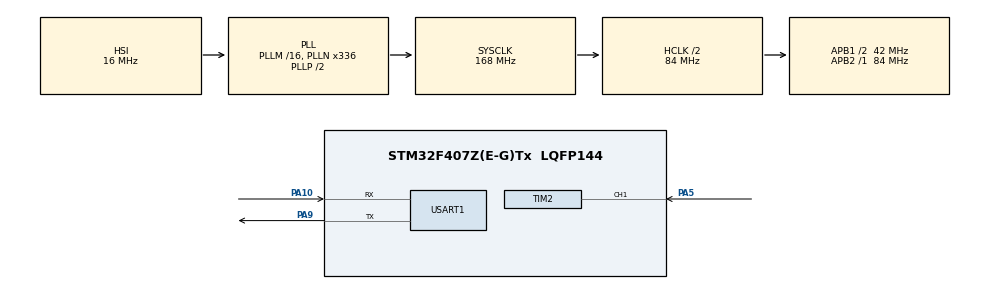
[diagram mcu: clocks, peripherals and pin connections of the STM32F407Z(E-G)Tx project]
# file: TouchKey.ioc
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Mcu.Family=STM32F4
Mcu.Name=STM32F407Z(E-G)Tx
Mcu.Package=LQFP144
NVIC.PriorityGroup=NVIC_PRIORITYGROUP_4
NVIC.TIM2_IRQn=true\:0\:0\:false\:false\:true\:true\:true
PA10.Mode=Asynchronous
PA10.Signal=USART1_RX
PA5.GPIO_Speed=GPIO_SPEED_FREQ_HIGH
PA5.Signal=S_TIM2_CH1_ETR
PA9.Mode=Asynchronous
PA9.Signal=USART1_TX
PC14-OSC32_IN.Mode=LSE-External-Oscillator
PC14-OSC32_IN.Signal=RCC_OSC32_IN
PC15-OSC32_OUT.Mode=LSE-External-Oscillator
PC15-OSC32_OUT.Signal=RCC_OSC32_OUT
PH0-OSC_IN.Mode=HSE-External-Oscillator
PH0-OSC_IN.Signal=RCC_OSC_IN
PH1-OSC_OUT.Mode=HSE-External-Oscillator
PH1-OSC_OUT.Signal=RCC_OSC_OUT
ProjectManager.HeapSize=0x200
ProjectManager.StackSize=0x400
ProjectManager.TargetToolchain=MDK-ARM V5
RCC.48MHZClocksFreq_Value=84000000
RCC.AHBCLKDivider=RCC_SYSCLK_DIV2
RCC.AHBFreq_Value=84000000
RCC.APB1CLKDivider=RCC_HCLK_DIV2
RCC.APB1Freq_Value=42000000
RCC.APB1TimFreq_Value=84000000
RCC.APB2Freq_Value=84000000
RCC.APB2TimFreq_Value=84000000
RCC.CortexFreq_Value=84000000
RCC.HCLKFreq_Value=84000000
RCC.HSE_VALUE=25000000
RCC.HSI_VALUE=16000000
RCC.PLLN=336
RCC.SYSCLKFreq_VALUE=168000000
RCC.SYSCLKSource=RCC_SYSCLKSOURCE_PLLCLK
RCC.VCOOutputFreq_Value=336000000
SH.S_TIM2_CH1_ETR.0=TIM2_CH1,Input_Capture1_from_TI1
TIM2.AutoReloadPreload=TIM_AUTORELOAD_PRELOAD_ENABLE
TIM2.Channel-Input_Capture1_from_TI1=TIM_CHANNEL_1
TIM2.ICFilter_CH1=2
TIM2.Period=1000000000
TIM2.Prescaler=8
USART1.VirtualMode=VM_ASYNC
VP_TIM2_VS_ClockSourceINT.Mode=Internal
board=custom

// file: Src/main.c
/* USER CODE BEGIN Header */
/**
  ******************************************************************************
  * @file           : main.c
  * @brief          : Main program body
  ******************************************************************************
  * @attention
  *
  * <h2><center>&copy; Copyright (c) 2019 STMicroelectronics.
  * All rights reserved.</center></h2>
  *
  * This software component is licensed by ST under BSD 3-Clause license,
  * the "License"; You may not use this file except in compliance with the
  * License. You may obtain a copy of the License at:
  *                        opensource.org/licenses/BSD-3-Clause
  *
  ******************************************************************************
  */
/* USER CODE END Header */

#include "main.h"

/* USER CODE BEGIN Includes */
#include <stdio.h>
#include "TPAD.h"
/* USER CODE END Includes */

/* USER CODE BEGIN PD */
#define TIMEOUT_MAX		1000000000
/* USER CODE END PD */

TIM_HandleTypeDef htim2;

UART_HandleTypeDef huart1;

void SystemClock_Config(void);
static void MX_GPIO_Init(void);
static void MX_TIM2_Init(void);
static void MX_USART1_UART_Init(void);

int main(void)
{
  /* USER CODE BEGIN 1 */
	uint32_t tmp;
  /* USER CODE END 1 */

  /* MCU Configuration--------------------------------------------------------*/

  /* Reset of all peripherals, Initializes the Flash interface and the Systick. */
  HAL_Init();

  /* Configure the system clock */
  SystemClock_Config();

  /* Initialize all configured peripherals */
  MX_GPIO_Init();
  MX_TIM2_Init();
  MX_USART1_UART_Init();
  /* USER CODE BEGIN 2 */
	HAL_TIM_IC_Start_IT(&htim2, TIM_CHANNEL_1);

  /* USER CODE END 2 */

  /* Infinite loop */
  /* USER CODE BEGIN WHILE */
  while (1)
  {

		if(TouchKeyScan(1))
		{
			printf("按下\r\n");
			HAL_Delay(10);
		}
    /* USER CODE END WHILE */

  }
}

void SystemClock_Config(void)
{
  RCC_OscInitTypeDef RCC_OscInitStruct = {0};
  RCC_ClkInitTypeDef RCC_ClkInitStruct = {0};

  /** Configure the main internal regulator output voltage
  */
  __HAL_RCC_PWR_CLK_ENABLE();
  __HAL_PWR_VOLTAGESCALING_CONFIG(PWR_REGULATOR_VOLTAGE_SCALE1);
  /** Initializes the CPU, AHB and APB busses clocks
  */
  RCC_OscInitStruct.OscillatorType = RCC_OSCILLATORTYPE_HSI;
  RCC_OscInitStruct.HSIState = RCC_HSI_ON;
  RCC_OscInitStruct.HSICalibrationValue = RCC_HSICALIBRATION_DEFAULT;
  RCC_OscInitStruct.PLL.PLLState = RCC_PLL_ON;
  RCC_OscInitStruct.PLL.PLLSource = RCC_PLLSOURCE_HSI;
  RCC_OscInitStruct.PLL.PLLM = 16;
  RCC_OscInitStruct.PLL.PLLN = 336;
  RCC_OscInitStruct.PLL.PLLP = RCC_PLLP_DIV2;
  RCC_OscInitStruct.PLL.PLLQ = 4;
  if (HAL_RCC_OscConfig(&RCC_OscInitStruct) != HAL_OK)
  {
    Error_Handler();
  }
  /** Initializes the CPU, AHB and APB busses clocks
  */
  RCC_ClkInitStruct.ClockType = RCC_CLOCKTYPE_HCLK|RCC_CLOCKTYPE_SYSCLK
                              |RCC_CLOCKTYPE_PCLK1|RCC_CLOCKTYPE_PCLK2;
  RCC_ClkInitStruct.SYSCLKSource = RCC_SYSCLKSOURCE_PLLCLK;
  RCC_ClkInitStruct.AHBCLKDivider = RCC_SYSCLK_DIV2;
  RCC_ClkInitStruct.APB1CLKDivider = RCC_HCLK_DIV2;
  RCC_ClkInitStruct.APB2CLKDivider = RCC_HCLK_DIV1;

  if (HAL_RCC_ClockConfig(&RCC_ClkInitStruct, FLASH_LATENCY_2) != HAL_OK)
  {
    Error_Handler();
  }
}

static void MX_TIM2_Init(void)
{

  TIM_ClockConfigTypeDef sClockSourceConfig = {0};
  TIM_MasterConfigTypeDef sMasterConfig = {0};
  TIM_IC_InitTypeDef sConfigIC = {0};

  htim2.Instance = TIM2;
  htim2.Init.Prescaler = 8;
  htim2.Init.CounterMode = TIM_COUNTERMODE_UP;
  htim2.Init.Period = 1000000000;
  htim2.Init.ClockDivision = TIM_CLOCKDIVISION_DIV1;
  htim2.Init.AutoReloadPreload = TIM_AUTORELOAD_PRELOAD_ENABLE;
  if (HAL_TIM_Base_Init(&htim2) != HAL_OK)
  {
    Error_Handler();
  }
  sClockSourceConfig.ClockSource = TIM_CLOCKSOURCE_INTERNAL;
  if (HAL_TIM_ConfigClockSource(&htim2, &sClockSourceConfig) != HAL_OK)
  {
    Error_Handler();
  }
  if (HAL_TIM_IC_Init(&htim2) != HAL_OK)
  {
    Error_Handler();
  }
  sMasterConfig.MasterOutputTrigger = TIM_TRGO_RESET;
  sMasterConfig.MasterSlaveMode = TIM_MASTERSLAVEMODE_DISABLE;
  if (HAL_TIMEx_MasterConfigSynchronization(&htim2, &sMasterConfig) != HAL_OK)
  {
    Error_Handler();
  }
  sConfigIC.ICPolarity = TIM_INPUTCHANNELPOLARITY_RISING;
  sConfigIC.ICSelection = TIM_ICSELECTION_DIRECTTI;
  sConfigIC.ICPrescaler = TIM_ICPSC_DIV1;
  sConfigIC.ICFilter = 2;
  if (HAL_TIM_IC_ConfigChannel(&htim2, &sConfigIC, TIM_CHANNEL_1) != HAL_OK)
  {
    Error_Handler();
  }

}

static void MX_USART1_UART_Init(void)
{

  huart1.Instance = USART1;
  huart1.Init.BaudRate = 115200;
  huart1.Init.WordLength = UART_WORDLENGTH_8B;
  huart1.Init.StopBits = UART_STOPBITS_1;
  huart1.Init.Parity = UART_PARITY_NONE;
  huart1.Init.Mode = UART_MODE_TX_RX;
  huart1.Init.HwFlowCtl = UART_HWCONTROL_NONE;
  huart1.Init.OverSampling = UART_OVERSAMPLING_16;
  if (HAL_UART_Init(&huart1) != HAL_OK)
  {
    Error_Handler();
  }

}

static void MX_GPIO_Init(void)
{

  /* GPIO Ports Clock Enable */
  __HAL_RCC_GPIOC_CLK_ENABLE();
  __HAL_RCC_GPIOH_CLK_ENABLE();
  __HAL_RCC_GPIOA_CLK_ENABLE();

}

/* USER CODE BEGIN 4 */
void HAL_TIM_IC_CaptureCallback(TIM_HandleTypeDef *htim)
{
  /* Prevent unused argument(s) compilation warning */
  UNUSED(htim);

  /* NOTE : This function should not be modified, when the callback is needed,
            the HAL_TIM_IC_CaptureCallback could be implemented in the user file
   */
	if(startIC_State == 1)
	{
		getValue = HAL_TIM_ReadCapturedValue(&htim2, TIM_CHANNEL_1);
		finishIC_State = 1;
	}
}

void HAL_TIM_PeriodElapsedCallback(TIM_HandleTypeDef *htim)
{
  /* Prevent unused argument(s) compilation warning */
  UNUSED(htim);

  /* NOTE : This function should not be modified, when the callback is needed,
            the HAL_TIM_PeriodElapsedCallback could be implemented in the user file
   */
	if(startIC_State == 1)
	{
		getValue = 1000000000;
		finishIC_State = 1;
	}
}

//重定义fputc函数
int fputc(int ch, FILE *f)
{
	while((USART1->SR&0X40)==0);//循环发送,直到发送完毕
	USART1->DR = (uint8_t) ch;
	return ch;
}
/* USER CODE END 4 */

void Error_Handler(void)
{
}

/************************ (C) COPYRIGHT STMicroelectronics *****END OF FILE****/
